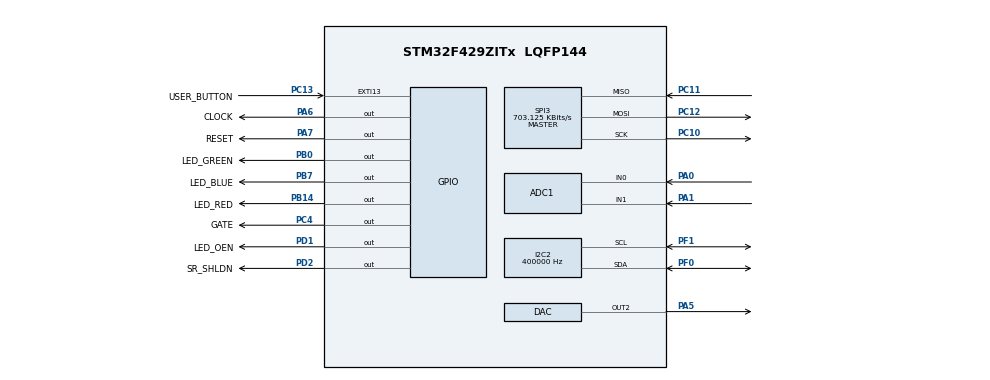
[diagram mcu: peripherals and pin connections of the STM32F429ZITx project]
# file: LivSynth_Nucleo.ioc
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ADC1.Channel-0\#ChannelRegularConversion=ADC_CHANNEL_0
ADC1.Channel-1\#ChannelRegularConversion=ADC_CHANNEL_1
ADC1.ContinuousConvMode=ENABLE
ADC1.DMAContinuousRequests=ENABLE
ADC1.NbrOfConversion=2
ADC1.NbrOfConversionFlag=1
ADC1.Rank-0\#ChannelRegularConversion=1
ADC1.Rank-1\#ChannelRegularConversion=2
ADC1.SamplingTime-0\#ChannelRegularConversion=ADC_SAMPLETIME_480CYCLES
ADC1.SamplingTime-1\#ChannelRegularConversion=ADC_SAMPLETIME_480CYCLES
ADC1.ScanConvMode=ENABLE
ADC1.master=1
DAC.DAC_Trigger2=DAC_TRIGGER_SOFTWARE
Dma.ADC1.0.Direction=DMA_PERIPH_TO_MEMORY
Dma.ADC1.0.FIFOMode=DMA_FIFOMODE_DISABLE
Dma.ADC1.0.Instance=DMA2_Stream0
Dma.ADC1.0.MemDataAlignment=DMA_MDATAALIGN_HALFWORD
Dma.ADC1.0.MemInc=DMA_MINC_ENABLE
Dma.ADC1.0.Mode=DMA_CIRCULAR
Dma.ADC1.0.PeriphDataAlignment=DMA_PDATAALIGN_HALFWORD
Dma.ADC1.0.PeriphInc=DMA_PINC_DISABLE
Dma.ADC1.0.Priority=DMA_PRIORITY_LOW
Dma.I2C2_TX.1.Direction=DMA_MEMORY_TO_PERIPH
Dma.I2C2_TX.1.FIFOMode=DMA_FIFOMODE_DISABLE
Dma.I2C2_TX.1.Instance=DMA1_Stream7
Dma.I2C2_TX.1.MemDataAlignment=DMA_MDATAALIGN_BYTE
Dma.I2C2_TX.1.MemInc=DMA_MINC_ENABLE
Dma.I2C2_TX.1.Mode=DMA_NORMAL
Dma.I2C2_TX.1.PeriphDataAlignment=DMA_PDATAALIGN_BYTE
Dma.I2C2_TX.1.PeriphInc=DMA_PINC_DISABLE
Dma.I2C2_TX.1.Priority=DMA_PRIORITY_LOW
Dma.Request0=ADC1
Dma.Request1=I2C2_TX
I2C2.ClockSpeed=400000
I2C2.I2C_Mode=I2C_Fast
Mcu.Family=STM32F4
Mcu.Name=STM32F429ZITx
Mcu.Package=LQFP144
NVIC.DMA1_Stream7_IRQn=true\:0\:0\:false\:false\:true\:false\:true\:true
NVIC.DMA2_Stream0_IRQn=true\:0\:0\:false\:true\:true\:2\:false\:true\:true
NVIC.EXTI15_10_IRQn=true\:0\:0\:false\:true\:true\:3\:true\:true\:true
NVIC.PriorityGroup=NVIC_PRIORITYGROUP_4
NVIC.TIM5_IRQn=true\:0\:0\:false\:false\:true\:true\:true\:true
PA0/WKUP.Signal=ADCx_IN0
PA1.Signal=ADCx_IN1
PA13.Mode=Trace_Asynchronous_SW
PA13.Signal=SYS_JTMS-SWDIO
PA14.Mode=Trace_Asynchronous_SW
PA14.Signal=SYS_JTCK-SWCLK
PA5.Signal=COMP_DAC2_group
PA6.GPIO_Label=CLOCK
PA6.Signal=GPIO_Output
PA7.GPIO_Label=RESET
PA7.Signal=GPIO_Output
PB0.GPIO_Label=LED_GREEN
PB0.Signal=GPIO_Output
PB14.GPIO_Label=LED_RED
PB14.Signal=GPIO_Output
PB3.Mode=Trace_Asynchronous_SW
PB3.Signal=SYS_JTDO-SWO
PB7.GPIO_Label=LED_BLUE
PB7.Signal=GPIO_Output
PC10.Mode=Full_Duplex_Master
PC10.Signal=SPI3_SCK
PC11.Mode=Full_Duplex_Master
PC11.Signal=SPI3_MISO
PC12.Mode=Full_Duplex_Master
PC12.Signal=SPI3_MOSI
PC13.GPIO_Label=USER_BUTTON
PC13.GPIO_ModeDefaultEXTI=GPIO_MODE_IT_RISING
PC13.Signal=GPXTI13
PC4.GPIO_Label=GATE
PC4.Signal=GPIO_Output
PD1.GPIO_Label=LED_OEN
PD1.GPIO_PuPd=GPIO_PULLUP
PD1.Signal=GPIO_Output
PD2.GPIO_Label=SR_SHLDN
PD2.Signal=GPIO_Output
PF0.Mode=I2C
PF0.Signal=I2C2_SDA
PF1.Mode=I2C
PF1.Signal=I2C2_SCL
PH0/OSC_IN.Mode=HSE-External-Oscillator
PH0/OSC_IN.Signal=RCC_OSC_IN
PH1/OSC_OUT.Mode=HSE-External-Oscillator
PH1/OSC_OUT.Signal=RCC_OSC_OUT
ProjectManager.HeapSize=0x200
ProjectManager.StackSize=0x400
ProjectManager.TargetToolchain=STM32CubeIDE
RCC.48MHZClocksFreq_Value=90000000
RCC.AHBFreq_Value=180000000
RCC.APB1CLKDivider=RCC_HCLK_DIV4
RCC.APB1Freq_Value=45000000
RCC.APB1TimFreq_Value=90000000
RCC.APB2CLKDivider=RCC_HCLK_DIV2
RCC.APB2Freq_Value=90000000
RCC.APB2TimFreq_Value=180000000
RCC.CortexFreq_Value=180000000
RCC.HCLKFreq_Value=180000000
RCC.HSE_VALUE=8000000
RCC.HSI_VALUE=16000000
RCC.LSE_VALUE=32768
RCC.PLLM=4
RCC.PLLMUL=RCC_PLL_MUL9
RCC.PLLN=180
RCC.PLLSourceVirtual=RCC_PLLSOURCE_HSE
RCC.PRESCALERUSB=RCC_USBCLKSOURCE_PLL_DIV1_5
RCC.SYSCLKFreq_VALUE=180000000
RCC.SYSCLKSource=RCC_SYSCLKSOURCE_PLLCLK
RCC.SYSCLKSourceVirtual=RCC_SYSCLKSOURCE_PLLCLK
RCC.USBFreq_Value=48000000
RCC.VCOOutputFreq_Value=360000000
SH.ADCx_IN0.0=ADC1_IN0,IN0
SH.ADCx_IN1.0=ADC1_IN1,IN1
SH.COMP_DAC2_group.0=DAC_OUT2,DAC_OUT2
SPI3.BaudRatePrescaler=SPI_BAUDRATEPRESCALER_64
SPI3.CalculateBaudRate=703.125 KBits/s
SPI3.Direction=SPI_DIRECTION_2LINES
SPI3.Mode=SPI_MODE_MASTER
SPI3.VirtualType=VM_MASTER
TIM5.Period=2603
TIM5.Prescaler=89
VP_TIM5_VS_ClockSourceINT.Mode=Internal
board=NUCLEO-F429ZI

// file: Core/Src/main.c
/* USER CODE BEGIN Header */
/**
  ******************************************************************************
  * @file           : main.c
  * @brief          : Main program body
  ******************************************************************************
  * @attention
  *
  * Copyright (c) 2022 STMicroelectronics.
  * All rights reserved.
  *
  * This software is licensed under terms that can be found in the LICENSE file
  * in the root directory of this software component.
  * If no LICENSE file comes with this software, it is provided AS-IS.
  *
  ******************************************************************************
  */
/* USER CODE END Header */
#include "main.h"
#include "adc.h"
#include "dac.h"
#include "dma.h"
#include "i2c.h"
#include "spi.h"
#include "tim.h"
#include "gpio.h"

/* USER CODE BEGIN Includes */
#include "LivSynthMain.h"
#include <stdio.h>
/* USER CODE END Includes */

void SystemClock_Config(void);
static void MX_NVIC_Init(void);

int main(void)
{

  /* MCU Configuration--------------------------------------------------------*/

  /* Reset of all peripherals, Initializes the Flash interface and the Systick. */
  LL_APB2_GRP1_EnableClock(LL_APB2_GRP1_PERIPH_SYSCFG);
  LL_APB1_GRP1_EnableClock(LL_APB1_GRP1_PERIPH_PWR);

  /* System interrupt init*/
  NVIC_SetPriorityGrouping(NVIC_PRIORITYGROUP_4);

  /* Configure the system clock */
  SystemClock_Config();

  /* Initialize all configured peripherals */
  MX_GPIO_Init();
  MX_DAC_Init();
  MX_DMA_Init();
  MX_ADC1_Init();
  MX_SPI3_Init();
  MX_I2C2_Init();
  MX_TIM5_Init();

  /* Initialize interrupts */
  MX_NVIC_Init();

  /* Infinite loop */
  /* USER CODE BEGIN WHILE */
  appMain();
  while (1)
  {
    /* USER CODE END WHILE */

  }
}

void SystemClock_Config(void)
{
  LL_FLASH_SetLatency(LL_FLASH_LATENCY_5);
  while(LL_FLASH_GetLatency()!= LL_FLASH_LATENCY_5)
  {
  }
  LL_PWR_SetRegulVoltageScaling(LL_PWR_REGU_VOLTAGE_SCALE1);
  LL_PWR_EnableOverDriveMode();
  LL_RCC_HSE_Enable();

   /* Wait till HSE is ready */
  while(LL_RCC_HSE_IsReady() != 1)
  {

  }
  LL_RCC_PLL_ConfigDomain_SYS(LL_RCC_PLLSOURCE_HSE, LL_RCC_PLLM_DIV_4, 180, LL_RCC_PLLP_DIV_2);
  LL_RCC_PLL_Enable();

   /* Wait till PLL is ready */
  while(LL_RCC_PLL_IsReady() != 1)
  {

  }
  LL_RCC_SetAHBPrescaler(LL_RCC_SYSCLK_DIV_1);
  LL_RCC_SetAPB1Prescaler(LL_RCC_APB1_DIV_4);
  LL_RCC_SetAPB2Prescaler(LL_RCC_APB2_DIV_2);
  LL_RCC_SetSysClkSource(LL_RCC_SYS_CLKSOURCE_PLL);

   /* Wait till System clock is ready */
  while(LL_RCC_GetSysClkSource() != LL_RCC_SYS_CLKSOURCE_STATUS_PLL)
  {

  }
  LL_Init1msTick(180000000);
  LL_SetSystemCoreClock(180000000);
  LL_RCC_SetTIMPrescaler(LL_RCC_TIM_PRESCALER_TWICE);
}

/**
  * @brief NVIC Configuration.
  * @retval None
  */
static void MX_NVIC_Init(void)
{
  /* DMA2_Stream0_IRQn interrupt configuration */
  NVIC_SetPriority(DMA2_Stream0_IRQn, NVIC_EncodePriority(NVIC_GetPriorityGrouping(),0, 0));
  NVIC_EnableIRQ(DMA2_Stream0_IRQn);
  /* EXTI15_10_IRQn interrupt configuration */
  NVIC_SetPriority(EXTI15_10_IRQn, NVIC_EncodePriority(NVIC_GetPriorityGrouping(),0, 0));
  NVIC_EnableIRQ(EXTI15_10_IRQn);
}

void Error_Handler(void)
{
  __disable_irq();
  while (1)
  {
  }
}
